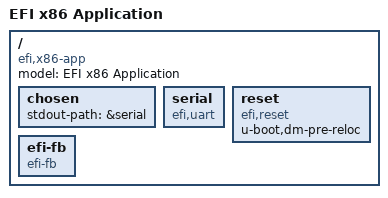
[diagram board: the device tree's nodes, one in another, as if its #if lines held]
// SPDX-License-Identifier: GPL-2.0+
/*
 * Copyright (c) 2015 Google, Inc
 */

/dts-v1/;

/include/ "skeleton.dtsi"

#include "tsc_timer.dtsi"

#if defined(CONFIG_CHROMEOS_VBOOT)
#include "chromeos-efi.dtsi"
#endif

/ {
	model = "EFI x86 Application";
	compatible = "efi,x86-app";

	chosen {
		stdout-path = &serial;
	};

	serial: serial {
		compatible = "efi,uart";
	};

	reset {
		compatible = "efi,reset";
		u-boot,dm-pre-reloc;
	};
	efi-fb {
		compatible = "efi-fb";
	};

};
